VERSION ""

NS_ :

BS_:

BU_: SensoricSolutionsOMSRace

BO_ 1538 PitchAndRoll: 4 SensoricSolutionsOMSRace
 SG_ Roll : 0|16@1- (0.003,0) [-90|90] "°" SensoricSolutionsOMSRace
 SG_ Pitch : 16|16@1- (0.003,0) [-90|90] "°" SensoricSolutionsOMSRace

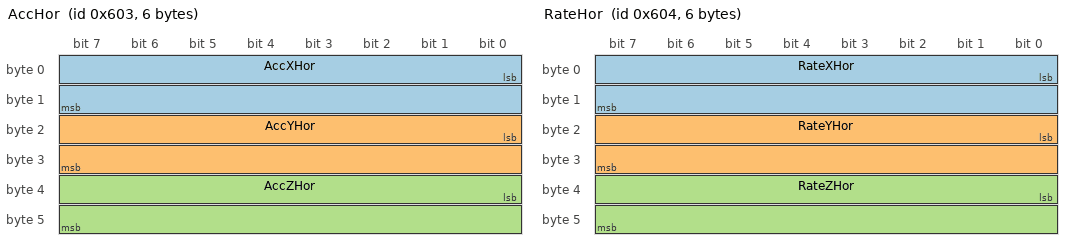
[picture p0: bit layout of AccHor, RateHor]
BO_ 1539 AccHor: 6 SensoricSolutionsOMSRace
 SG_ AccXHor : 0|16@1- (0.02,0) [-200.0|200.0] "m/s^2" SensoricSolutionsOMSRace
 SG_ AccYHor : 16|16@1- (0.02,0) [-200.0|200.0] "m/s^2" SensoricSolutionsOMSRace
 SG_ AccZHor : 32|16@1- (0.02,0) [-200.0|200.0] "m/s^2" SensoricSolutionsOMSRace

BO_ 1540 RateHor: 6 SensoricSolutionsOMSRace
 SG_ RateXHor : 0|16@1- (0.02,0) [-500.0|500.0] "°/s" SensoricSolutionsOMSRace
 SG_ RateYHor : 16|16@1- (0.02,0) [-500.0|500.0] "°/s" SensoricSolutionsOMSRace
 SG_ RateZHor : 32|16@1- (0.02,0) [-500.0|500.0] "°/s" SensoricSolutionsOMSRace

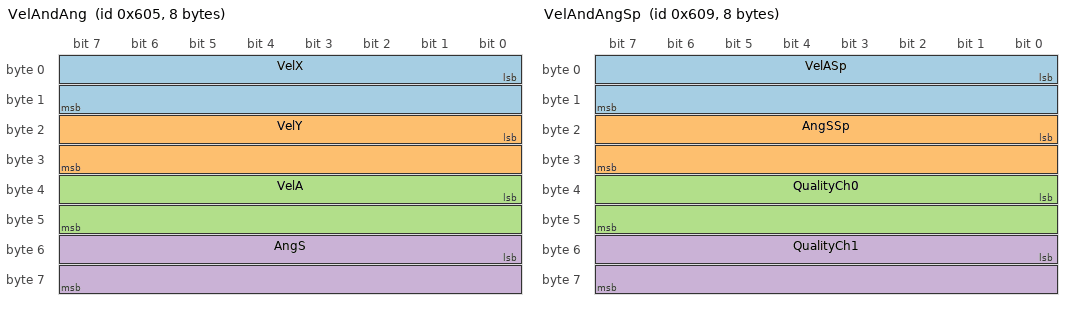
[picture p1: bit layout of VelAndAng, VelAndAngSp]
BO_ 1541 VelAndAng: 8 SensoricSolutionsOMSRace
 SG_ VelX : 0|16@1- (0.02,0) [-450|450] "km/h" SensoricSolutionsOMSRace
 SG_ VelY : 16|16@1- (0.02,0) [-100|100] "km/h" SensoricSolutionsOMSRace
 SG_ VelA : 32|16@1- (0.02,0) [0|450] "km/h" SensoricSolutionsOMSRace
 SG_ AngS : 48|16@1- (0.003,0) [-40|40] "°" SensoricSolutionsOMSRace

BO_ 1545 VelAndAngSp: 8 SensoricSolutionsOMSRace
 SG_ VelASp : 0|16@1- (0.02,0) [0|450] "km/h" SensoricSolutionsOMSRace
 SG_ AngSSp : 16|16@1- (0.003,0) [-40|40] "°" SensoricSolutionsOMSRace
 SG_ QualityCh0 : 32|16@1+ (1.0,0) [0|65535] "" SensoricSolutionsOMSRace
 SG_ QualityCh1 : 48|16@1+ (1.0,0) [0|65535] "" SensoricSolutionsOMSRace

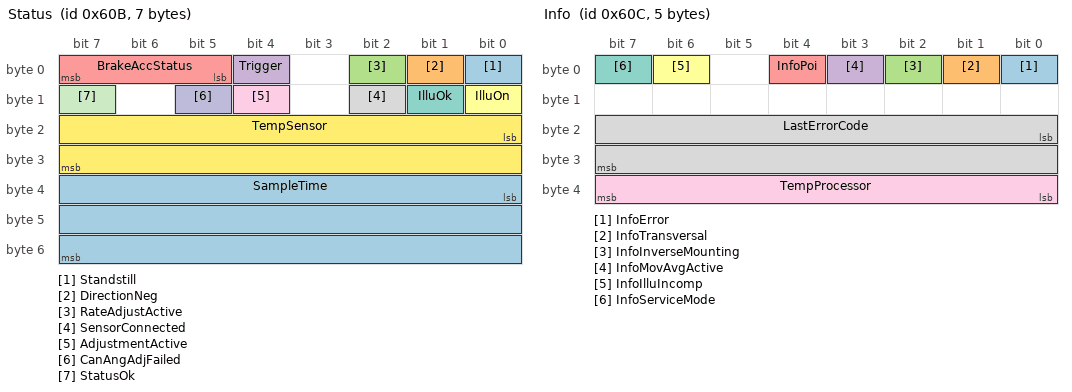
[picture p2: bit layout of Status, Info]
BO_ 1547 Status: 7 SensoricSolutionsOMSRace
 SG_ Standstill : 0|1@1+ (1,0) [0|1] "" SensoricSolutionsOMSRace
 SG_ DirectionNeg : 1|1@1+ (1,0) [0|1] "" SensoricSolutionsOMSRace
 SG_ RateAdjustActive : 2|1@1+ (1,0) [0|1] "" SensoricSolutionsOMSRace
 SG_ Trigger : 4|1@1+ (1,0) [0|1] "" SensoricSolutionsOMSRace
 SG_ BrakeAccStatus : 5|3@1+ (1,0) [0|5] "" SensoricSolutionsOMS7
 SG_ IlluOn : 8|1@1+ (1,0) [0|1] "" SensoricSolutionsOMSRace
 SG_ IlluOk : 9|1@1+ (1,0) [0|1] "" SensoricSolutionsOMSRace
 SG_ SensorConnected : 10|1@1+ (1,0) [0|1] "" SensoricSolutionsOMSRace
 SG_ AdjustmentActive : 12|1@1+ (1,0) [0|1] "" SensoricSolutionsOMSRace
 SG_ CanAngAdjFailed : 13|1@1+ (1,0) [0|1] "" SensoricSolutionsOMSRace
 SG_ StatusOk : 15|1@1+ (1,0) [0|1] "" SensoricSolutionsOMSRace
 SG_ TempSensor : 16|16@1- (0.1,0) [-20|85] "°C" SensoricSolutionsOMSRace
 SG_ SampleTime : 32|24@1+ (0.001,0) [0|16777.215] "s" SensoricSolutionsOMSRace

 BO_ 1548 Info: 5 SensoricSolutionsOMSRace
 SG_ InfoError : 0|1@1+ (1,0) [0|1] "" SensoricSolutionsOMSRace
 SG_ InfoTransversal : 1|1@1+ (1,0) [0|1] "" SensoricSolutionsOMSRace
 SG_ InfoInverseMounting : 2|1@1+ (1,0) [0|1] "" SensoricSolutionsOMSRace
 SG_ InfoMovAvgActive : 3|1@1+ (1,0) [0|1] "" SensoricSolutionsOMSRace
 SG_ InfoPoi : 4|1@1+ (1,0) [0|1] "" SensoricSolutionsOMSRace
 SG_ InfoIlluIncomp : 6|1@1+ (1,0) [0|1] "" SensoricSolutionsOMSRace
 SG_ InfoServiceMode : 7|1@1+ (1,0) [0|1] "" SensoricSolutionsOMSRace
 SG_ LastErrorCode : 16|16@1+ (1,0) [0|65535] "" SensoricSolutionsOMSRace
 SG_ TempProcessor : 32|8@1- (1,0) [-128|127] "°C" SensoricSolutionsOMSRace

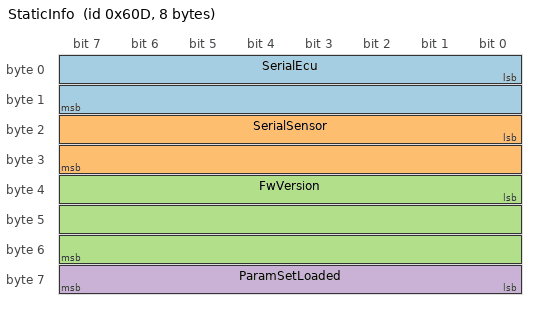
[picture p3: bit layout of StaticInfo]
BO_ 1549 StaticInfo: 8 SensoricSolutionsOMSRace
 SG_ SerialEcu : 0|16@1+ (1,0) [0|65535] "" SensoricSolutionsOMSRace
 SG_ SerialSensor : 16|16@1+ (1,0) [0|65535] "" SensoricSolutionsOMSRace
 SG_ FwVersion : 32|24@1+ (1,0) [0|16777215] "" SensoricSolutionsOMSRace
 SG_ ParamSetLoaded : 56|8@1+ (1,0) [0|255] "" SensoricSolutionsOMSRace

BA_DEF_ BO_ "GenMsgCycleTimeus" INT 100 60000000;
BA_DEF_DEF_  "GenMsgCycleTimeus" 1000;

BA_ "GenMsgCycleTimeus" BO_ 1548 1000000;
BA_ "GenMsgCycleTimeus" BO_ 1549 1000000;
